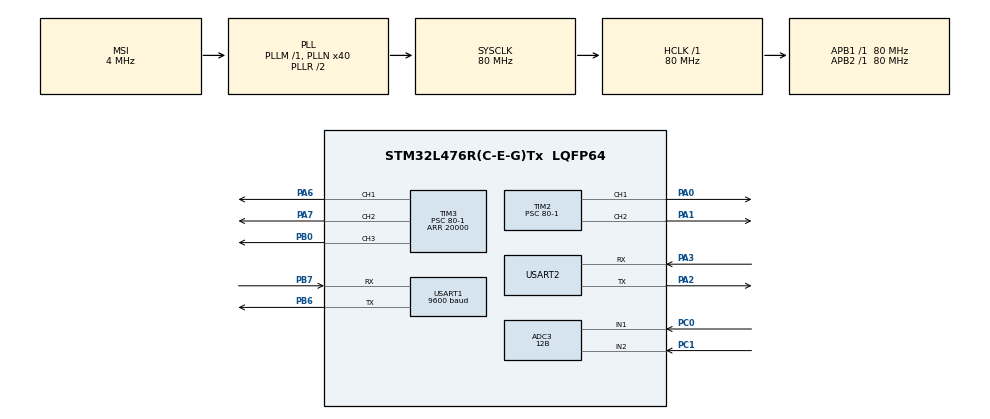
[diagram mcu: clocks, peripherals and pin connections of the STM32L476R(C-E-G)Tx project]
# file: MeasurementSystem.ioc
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ADC3.Channel-2\#ChannelRegularConversion=ADC_CHANNEL_1
ADC3.Channel-3\#ChannelRegularConversion=ADC_CHANNEL_2
ADC3.ClockPrescaler=ADC_CLOCK_SYNC_PCLK_DIV4
ADC3.ContinuousConvMode=ENABLE
ADC3.DMAContinuousRequests=ENABLE
ADC3.DataAlign=ADC_DATAALIGN_RIGHT
ADC3.EOCSelection=ADC_EOC_SINGLE_CONV
ADC3.EnableRegularConversion=ENABLE
ADC3.NbrOfConversion=2
ADC3.NbrOfConversionFlag=1
ADC3.OffsetNumber-2\#ChannelRegularConversion=ADC_OFFSET_NONE
ADC3.OffsetNumber-3\#ChannelRegularConversion=ADC_OFFSET_NONE
ADC3.Overrun=ADC_OVR_DATA_PRESERVED
ADC3.OversamplingMode=DISABLE
ADC3.Rank-2\#ChannelRegularConversion=1
ADC3.Rank-3\#ChannelRegularConversion=2
ADC3.Resolution=ADC_RESOLUTION_12B
ADC3.SamplingTime-2\#ChannelRegularConversion=ADC_SAMPLETIME_47CYCLES_5
ADC3.SamplingTime-3\#ChannelRegularConversion=ADC_SAMPLETIME_47CYCLES_5
Dma.ADC3.0.Direction=DMA_PERIPH_TO_MEMORY
Dma.ADC3.0.Instance=DMA1_Channel3
Dma.ADC3.0.MemDataAlignment=DMA_MDATAALIGN_HALFWORD
Dma.ADC3.0.MemInc=DMA_MINC_ENABLE
Dma.ADC3.0.Mode=DMA_CIRCULAR
Dma.ADC3.0.PeriphDataAlignment=DMA_PDATAALIGN_HALFWORD
Dma.ADC3.0.PeriphInc=DMA_PINC_DISABLE
Dma.ADC3.0.Priority=DMA_PRIORITY_LOW
Dma.Request0=ADC3
Mcu.Family=STM32L4
Mcu.Name=STM32L476R(C-E-G)Tx
Mcu.Package=LQFP64
NVIC.DMA1_Channel3_IRQn=true\:0\:0\:false\:false\:true\:false\:true
NVIC.PriorityGroup=NVIC_PRIORITYGROUP_4
NVIC.USART1_IRQn=true\:0\:0\:false\:false\:true\:true\:true
NVIC.USART2_IRQn=true\:0\:0\:false\:false\:true\:true\:true
PA0.Signal=S_TIM2_CH1
PA1.Signal=S_TIM2_CH2
PA13\ (JTMS-SWDIO).Mode=Serial_Wire
PA13\ (JTMS-SWDIO).Signal=SYS_JTMS-SWDIO
PA14\ (JTCK-SWCLK).Mode=Serial_Wire
PA14\ (JTCK-SWCLK).Signal=SYS_JTCK-SWCLK
PA2.Mode=Asynchronous
PA2.Signal=USART2_TX
PA3.Mode=Asynchronous
PA3.Signal=USART2_RX
PA6.Signal=S_TIM3_CH1
PA7.Signal=S_TIM3_CH2
PB0.Signal=S_TIM3_CH3
PB6.Mode=Asynchronous
PB6.Signal=USART1_TX
PB7.Mode=Asynchronous
PB7.Signal=USART1_RX
PC0.Signal=ADCx_IN1
PC1.Signal=ADCx_IN2
ProjectManager.HeapSize=0x200
ProjectManager.StackSize=0x400
ProjectManager.TargetToolchain=STM32CubeIDE
RCC.ADCFreq_Value=32000000
RCC.AHBFreq_Value=80000000
RCC.APB1Freq_Value=80000000
RCC.APB1TimFreq_Value=80000000
RCC.APB2Freq_Value=80000000
RCC.APB2TimFreq_Value=80000000
RCC.CortexFreq_Value=80000000
RCC.HCLKFreq_Value=80000000
RCC.HSE_VALUE=8000000
RCC.HSI_VALUE=16000000
RCC.LSE_VALUE=32768
RCC.MSI_VALUE=4000000
RCC.PLLN=40
RCC.PLLSAI1N=16
RCC.SYSCLKFreq_VALUE=80000000
RCC.SYSCLKSource=RCC_SYSCLKSOURCE_PLLCLK
RCC.USBFreq_Value=32000000
RCC.VCOOutputFreq_Value=160000000
SH.ADCx_IN1.0=ADC3_IN1,IN1-Single-Ended
SH.ADCx_IN2.0=ADC3_IN2,IN2-Single-Ended
SH.S_TIM2_CH1.0=TIM2_CH1,PWM Generation1 CH1
SH.S_TIM2_CH2.0=TIM2_CH2,PWM Generation2 CH2
SH.S_TIM3_CH1.0=TIM3_CH1,PWM Generation1 CH1
SH.S_TIM3_CH2.0=TIM3_CH2,PWM Generation2 CH2
SH.S_TIM3_CH3.0=TIM3_CH3,PWM Generation3 CH3
TIM2.Channel-PWM\ Generation1\ CH1=TIM_CHANNEL_1
TIM2.Channel-PWM\ Generation2\ CH2=TIM_CHANNEL_2
TIM2.Period=20000-1
TIM2.Prescaler=80-1
TIM2.Pulse-PWM\ Generation1\ CH1=1000
TIM2.Pulse-PWM\ Generation2\ CH2=1000
TIM3.Channel-PWM\ Generation1\ CH1=TIM_CHANNEL_1
TIM3.Channel-PWM\ Generation2\ CH2=TIM_CHANNEL_2
TIM3.Channel-PWM\ Generation3\ CH3=TIM_CHANNEL_3
TIM3.Period=20000
TIM3.Prescaler=80-1
TIM3.Pulse-PWM\ Generation1\ CH1=1000
TIM3.Pulse-PWM\ Generation2\ CH2=1000
TIM3.Pulse-PWM\ Generation3\ CH3=1000
USART1.BaudRate=9600
USART1.VirtualMode-Asynchronous=VM_ASYNC
USART2.VirtualMode-Asynchronous=VM_ASYNC
board=custom

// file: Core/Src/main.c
/* USER CODE BEGIN Header */
/**
  ******************************************************************************
  * @file           : main.c
  * @brief          : Main program body
  ******************************************************************************
  * @attention
  *
  * <h2><center>&copy; Copyright (c) 2023 STMicroelectronics.
  * All rights reserved.</center></h2>
  *
  * This software component is licensed by ST under BSD 3-Clause license,
  * the "License"; You may not use this file except in compliance with the
  * License. You may obtain a copy of the License at:
  *                        opensource.org/licenses/BSD-3-Clause
  *
  ******************************************************************************
  */
/* USER CODE END Header */
#include "main.h"
#include "adc.h"
#include "dma.h"
#include "tim.h"
#include "usart.h"
#include "gpio.h"

/* USER CODE BEGIN Includes */

#include "stdio.h"
#include "Supercluster_Body.h"

/* USER CODE END Includes */

void SystemClock_Config(void);

int main(void)
{

  /* MCU Configuration--------------------------------------------------------*/

  /* Reset of all peripherals, Initializes the Flash interface and the Systick. */
  HAL_Init();

  /* Configure the system clock */
  SystemClock_Config();

  /* Initialize all configured peripherals */
  MX_GPIO_Init();
  MX_DMA_Init();
  MX_USART1_UART_Init();
  MX_USART2_UART_Init();
  MX_ADC3_Init();
  MX_TIM2_Init();
  MX_TIM3_Init();
  /* USER CODE BEGIN 2 */

  Supercluster_Init();

  /* USER CODE END 2 */

  /* Infinite loop */
  /* USER CODE BEGIN WHILE */
  while (1)
  {
	  Supercluster_Body_Loop();

    /* USER CODE END WHILE */

  }
}

void SystemClock_Config(void)
{
  RCC_OscInitTypeDef RCC_OscInitStruct = {0};
  RCC_ClkInitTypeDef RCC_ClkInitStruct = {0};

  /** Configure the main internal regulator output voltage
  */
  if (HAL_PWREx_ControlVoltageScaling(PWR_REGULATOR_VOLTAGE_SCALE1) != HAL_OK)
  {
    Error_Handler();
  }
  /** Initializes the RCC Oscillators according to the specified parameters
  * in the RCC_OscInitTypeDef structure.
  */
  RCC_OscInitStruct.OscillatorType = RCC_OSCILLATORTYPE_MSI;
  RCC_OscInitStruct.MSIState = RCC_MSI_ON;
  RCC_OscInitStruct.MSICalibrationValue = 0;
  RCC_OscInitStruct.MSIClockRange = RCC_MSIRANGE_6;
  RCC_OscInitStruct.PLL.PLLState = RCC_PLL_ON;
  RCC_OscInitStruct.PLL.PLLSource = RCC_PLLSOURCE_MSI;
  RCC_OscInitStruct.PLL.PLLM = 1;
  RCC_OscInitStruct.PLL.PLLN = 40;
  RCC_OscInitStruct.PLL.PLLP = RCC_PLLP_DIV7;
  RCC_OscInitStruct.PLL.PLLQ = RCC_PLLQ_DIV2;
  RCC_OscInitStruct.PLL.PLLR = RCC_PLLR_DIV2;
  if (HAL_RCC_OscConfig(&RCC_OscInitStruct) != HAL_OK)
  {
    Error_Handler();
  }
  /** Initializes the CPU, AHB and APB buses clocks
  */
  RCC_ClkInitStruct.ClockType = RCC_CLOCKTYPE_HCLK|RCC_CLOCKTYPE_SYSCLK
                              |RCC_CLOCKTYPE_PCLK1|RCC_CLOCKTYPE_PCLK2;
  RCC_ClkInitStruct.SYSCLKSource = RCC_SYSCLKSOURCE_PLLCLK;
  RCC_ClkInitStruct.AHBCLKDivider = RCC_SYSCLK_DIV1;
  RCC_ClkInitStruct.APB1CLKDivider = RCC_HCLK_DIV1;
  RCC_ClkInitStruct.APB2CLKDivider = RCC_HCLK_DIV1;

  if (HAL_RCC_ClockConfig(&RCC_ClkInitStruct, FLASH_LATENCY_4) != HAL_OK)
  {
    Error_Handler();
  }
}

void Error_Handler(void)
{
  __disable_irq();
  while (1)
  {
  }
}

/************************ (C) COPYRIGHT STMicroelectronics *****END OF FILE****/
